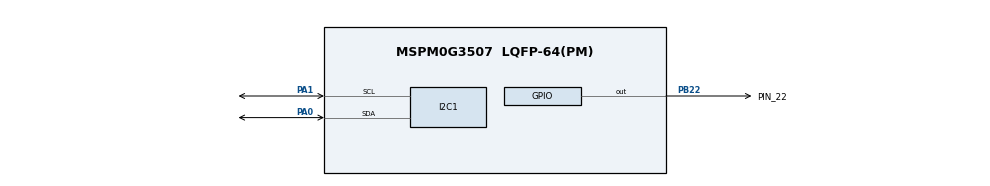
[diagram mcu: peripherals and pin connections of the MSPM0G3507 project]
/**
 * These arguments were used when this file was generated. They will be automatically applied on subsequent loads
 * via the GUI or CLI. Run CLI with '--help' for additional information on how to override these arguments.
 * @cliArgs --device "MSPM0G350X" --part "Default" --package "LQFP-64(PM)" --product "mspm0_sdk@2.10.00.04"
 * @v2CliArgs --device "MSPM0G3507" --package "LQFP-64(PM)" --product "mspm0_sdk@2.10.00.04"
 * @versions {"tool":"1.26.2+4477"}
 */

const GPIO    = scripting.addModule("/ti/driverlib/GPIO", {}, false);
const GPIO1   = GPIO.addInstance();
const I2C     = scripting.addModule("/ti/driverlib/I2C", {}, false);
const I2C1    = I2C.addInstance();
const SYSTICK = scripting.addModule("/ti/driverlib/SYSTICK");
const SYSCTL  = scripting.addModule("/ti/driverlib/SYSCTL");

GPIO1.$name                         = "LED1";
GPIO1.associatedPins[0].$name       = "PIN_22";
GPIO1.associatedPins[0].pin.$assign = "PB22";

I2C1.$name                         = "I2C";
I2C1.basicEnableController         = true;
I2C1.basicControllerBusSpeed       = 100000;
I2C1.advDigitalGlitchFilter        = "CLOCKS_1";
I2C1.advControllerRXFIFOTRIG       = "BYTES_8";
I2C1.advControllerTXFIFOTRIG       = "BYTES_7";
I2C1.enableDMAEvent1               = false;
I2C1.enableDMAEvent2               = false;
I2C1.peripheral.sdaPin.$assign     = "PA0";
I2C1.peripheral.sclPin.$assign     = "PA1";

SYSTICK.period          = 32000;
SYSTICK.periodEnable    = true;
SYSTICK.systickEnable   = true;
SYSTICK.interruptEnable = true;

const Board = scripting.addModule("/ti/driverlib/Board", {}, false);

SYSCTL.forceDefaultClkConfig = true;
Board.peripheral.$suggestSolution          = "DEBUGSS";
Board.peripheral.swclkPin.$suggestSolution = "PA20";
Board.peripheral.swdioPin.$suggestSolution = "PA19";
SYSCTL.peripheral.$suggestSolution         = "SYSCTL";
I2C1.peripheral.$suggestSolution           = "I2C0";
